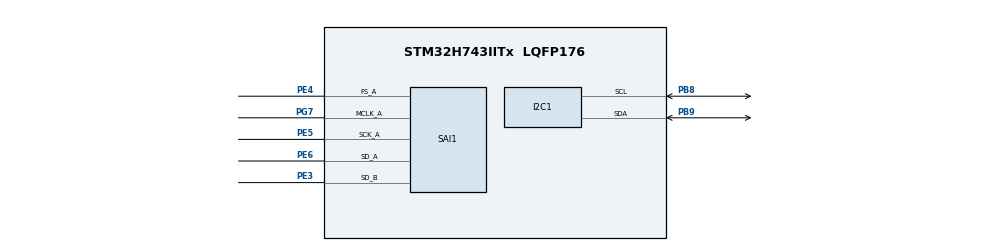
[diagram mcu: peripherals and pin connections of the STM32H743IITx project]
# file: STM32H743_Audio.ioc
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CORTEX_M7.AccessPermission-Cortex_Memory_Protection_Unit_Region1_Settings=MPU_REGION_FULL_ACCESS
CORTEX_M7.BaseAddress-Cortex_Memory_Protection_Unit_Region1_Settings=0x30000000
CORTEX_M7.CPU_DCache=Enabled
CORTEX_M7.CPU_ICache=Enabled
CORTEX_M7.DisableExec-Cortex_Memory_Protection_Unit_Region0_Settings=MPU_INSTRUCTION_ACCESS_DISABLE
CORTEX_M7.DisableExec-Cortex_Memory_Protection_Unit_Region1_Settings=MPU_INSTRUCTION_ACCESS_DISABLE
CORTEX_M7.Enable-Cortex_Memory_Protection_Unit_Region0_Settings=MPU_REGION_ENABLE
CORTEX_M7.Enable-Cortex_Memory_Protection_Unit_Region1_Settings=MPU_REGION_ENABLE
CORTEX_M7.IsBufferable-Cortex_Memory_Protection_Unit_Region1_Settings=MPU_ACCESS_NOT_BUFFERABLE
CORTEX_M7.IsCacheable-Cortex_Memory_Protection_Unit_Region1_Settings=MPU_ACCESS_NOT_CACHEABLE
CORTEX_M7.IsShareable-Cortex_Memory_Protection_Unit_Region0_Settings=MPU_ACCESS_SHAREABLE
CORTEX_M7.IsShareable-Cortex_Memory_Protection_Unit_Region1_Settings=MPU_ACCESS_SHAREABLE
CORTEX_M7.MPU_Control=MPU_PRIVILEGED_DEFAULT
CORTEX_M7.Size-Cortex_Memory_Protection_Unit_Region0_Settings=MPU_REGION_SIZE_4GB
CORTEX_M7.Size-Cortex_Memory_Protection_Unit_Region1_Settings=MPU_REGION_SIZE_32KB
CORTEX_M7.SubRegionDisable-Cortex_Memory_Protection_Unit_Region0_Settings=0x87
Dma.Request0=SAI1_A
Dma.Request1=SAI1_B
Dma.SAI1_A.0.Direction=DMA_MEMORY_TO_PERIPH
Dma.SAI1_A.0.EventEnable=DISABLE
Dma.SAI1_A.0.FIFOMode=DMA_FIFOMODE_DISABLE
Dma.SAI1_A.0.Instance=DMA2_Stream0
Dma.SAI1_A.0.MemDataAlignment=DMA_MDATAALIGN_WORD
Dma.SAI1_A.0.MemInc=DMA_MINC_ENABLE
Dma.SAI1_A.0.Mode=DMA_CIRCULAR
Dma.SAI1_A.0.PeriphDataAlignment=DMA_PDATAALIGN_WORD
Dma.SAI1_A.0.PeriphInc=DMA_PINC_DISABLE
Dma.SAI1_A.0.Polarity=HAL_DMAMUX_REQ_GEN_RISING
Dma.SAI1_A.0.Priority=DMA_PRIORITY_VERY_HIGH
Dma.SAI1_A.0.RequestNumber=1
Dma.SAI1_A.0.SignalID=NONE
Dma.SAI1_A.0.SyncEnable=DISABLE
Dma.SAI1_A.0.SyncPolarity=HAL_DMAMUX_SYNC_NO_EVENT
Dma.SAI1_A.0.SyncRequestNumber=1
Dma.SAI1_A.0.SyncSignalID=NONE
Dma.SAI1_B.1.Direction=DMA_PERIPH_TO_MEMORY
Dma.SAI1_B.1.EventEnable=DISABLE
Dma.SAI1_B.1.FIFOMode=DMA_FIFOMODE_DISABLE
Dma.SAI1_B.1.Instance=DMA2_Stream1
Dma.SAI1_B.1.MemDataAlignment=DMA_MDATAALIGN_WORD
Dma.SAI1_B.1.MemInc=DMA_MINC_ENABLE
Dma.SAI1_B.1.Mode=DMA_CIRCULAR
Dma.SAI1_B.1.PeriphDataAlignment=DMA_PDATAALIGN_WORD
Dma.SAI1_B.1.PeriphInc=DMA_PINC_DISABLE
Dma.SAI1_B.1.Polarity=HAL_DMAMUX_REQ_GEN_RISING
Dma.SAI1_B.1.Priority=DMA_PRIORITY_VERY_HIGH
Dma.SAI1_B.1.RequestNumber=1
Dma.SAI1_B.1.SignalID=NONE
Dma.SAI1_B.1.SyncEnable=DISABLE
Dma.SAI1_B.1.SyncPolarity=HAL_DMAMUX_SYNC_NO_EVENT
Dma.SAI1_B.1.SyncRequestNumber=1
Dma.SAI1_B.1.SyncSignalID=NONE
I2C1.Timing=0x10C0ECFF
Mcu.Family=STM32H7
Mcu.Name=STM32H743IITx
Mcu.Package=LQFP176
NVIC.DMA2_Stream0_IRQn=true\:5\:0\:false\:false\:true\:false\:true\:true
NVIC.DMA2_Stream1_IRQn=true\:5\:0\:false\:false\:true\:false\:true\:true
NVIC.PriorityGroup=NVIC_PRIORITYGROUP_4
PA13\ (JTMS/SWDIO).Mode=Serial_Wire
PA13\ (JTMS/SWDIO).Signal=DEBUG_JTMS-SWDIO
PA14\ (JTCK/SWCLK).Mode=Serial_Wire
PA14\ (JTCK/SWCLK).Signal=DEBUG_JTCK-SWCLK
PB8.GPIO_Speed=GPIO_SPEED_FREQ_VERY_HIGH
PB8.Mode=I2C
PB8.Signal=I2C1_SCL
PB9.GPIO_Speed=GPIO_SPEED_FREQ_VERY_HIGH
PB9.Mode=I2C
PB9.Signal=I2C1_SDA
PE3.GPIO_Speed=GPIO_SPEED_FREQ_VERY_HIGH
PE3.Mode=SAI_B_SyncSlave
PE3.Signal=SAI1_SD_B
PE4.GPIO_Speed=GPIO_SPEED_FREQ_VERY_HIGH
PE4.Mode=SAI_A_MasterWithClock
PE4.Signal=SAI1_FS_A
PE5.GPIO_Speed=GPIO_SPEED_FREQ_VERY_HIGH
PE5.Mode=SAI_A_MasterWithClock
PE5.Signal=SAI1_SCK_A
PE6.GPIO_Speed=GPIO_SPEED_FREQ_VERY_HIGH
PE6.Mode=SAI_A_MasterWithClock
PE6.Signal=SAI1_SD_A
PG7.GPIO_Speed=GPIO_SPEED_FREQ_VERY_HIGH
PG7.Mode=SAI_A_MasterWithClock
PG7.Signal=SAI1_MCLK_A
ProjectManager.HeapSize=0x200
ProjectManager.StackSize=0x400
ProjectManager.TargetToolchain=MDK-ARM V5.32
RCC.ADCFreq_Value=129000000
RCC.APB1Freq_Value=100000000
RCC.APB2Freq_Value=100000000
RCC.APB3Freq_Value=100000000
RCC.APB4Freq_Value=100000000
RCC.CortexFreq_Value=400000000
RCC.D1PPRE=RCC_APB3_DIV2
RCC.D2PPRE1=RCC_APB1_DIV2
RCC.D2PPRE2=RCC_APB2_DIV2
RCC.D3PPRE=RCC_APB4_DIV2
RCC.DIVM1=16
RCC.DIVM3=40
RCC.DIVN1=200
RCC.DIVN3=192
RCC.DIVP3=25
RCC.HCLKFreq_Value=200000000
RCC.HPRE=RCC_HCLK_DIV2
RCC.PLLSourceVirtual=RCC_PLLSOURCE_HSI
RCC.SAI1CLockSelection=RCC_SAI1CLKSOURCE_PLL3
RCC.SYSCLKFreq_VALUE=400000000
RCC.SYSCLKSource=RCC_SYSCLKSOURCE_PLLCLK
RCC.USBFreq_Value=400000000
SAI1.AudioFrequency-SAI_A_MasterWithClock=SAI_AUDIO_FREQUENCY_48K
SAI1.BasicDataSize-SAI_A_MasterWithClock=SAI_PROTOCOL_DATASIZE_24BIT
SAI1.BasicDataSize-SAI_B_SyncSlave=SAI_PROTOCOL_DATASIZE_24BIT
SAI1.BasicProtocol-SAI_A_MasterWithClock=SAI_I2S_STANDARD
SAI1.BasicProtocol-SAI_B_SyncSlave=SAI_I2S_STANDARD
SAI1.ErrorAudioFreq-SAI_A_MasterWithClock=0.0 %
SAI1.InitProtocol-SAI_A_MasterWithClock=Enable
SAI1.InitProtocol-SAI_B_SyncSlave=Enable
SAI1.Instance-SAI_A_MasterWithClock=SAI$Index_Block_A
SAI1.Instance-SAI_B_SyncSlave=SAI$Index_Block_B
SAI1.MClockEnable-SAI_A_MasterWithClock=SAI_MASTERCLOCK_ENABLE
SAI1.RealAudioFreq-SAI_A_MasterWithClock=48.0 KHz
SAI1.VirtualMode-SAI_A_MasterWithClock=VM_MASTER
SAI1.VirtualMode-SAI_B_SyncSlave=VM_SLAVE
SAI1.VirtualProtocol-SAI_A_BASIC=VM_BASIC_PROTOCOL
SAI1.VirtualProtocol-SAI_B_BASIC=VM_BASIC_PROTOCOL
VP_MEMORYMAP_VS_MEMORYMAP.Mode=CurAppReg
VP_SAI1_VP_$IpInstance_SAIA_SAI_BASIC.Mode=SAI_A_BASIC
VP_SAI1_VP_$IpInstance_SAIB_SAI_BASIC.Mode=SAI_B_BASIC
board=custom

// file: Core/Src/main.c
/* USER CODE BEGIN Header */
/**
  ******************************************************************************
  * @file           : main.c
  * @brief          : Main program body
  ******************************************************************************
  * @attention
  *
  * Copyright (c) 2026 STMicroelectronics.
  * All rights reserved.
  *
  * This software is licensed under terms that can be found in the LICENSE file
  * in the root directory of this software component.
  * If no LICENSE file comes with this software, it is provided AS-IS.
  *
  ******************************************************************************
  */
/* USER CODE END Header */
#include "main.h"
#include "dma.h"
#include "i2c.h"
#include "sai.h"
#include "gpio.h"

/* USER CODE BEGIN Includes */
#include "audio_app.h"
#if defined(AUDIO_BOARD_ENABLE_LVGL_UI) && AUDIO_BOARD_ENABLE_LVGL_UI
#include "lvgl_ui.h"
#endif

/* USER CODE END Includes */

void SystemClock_Config(void);
void PeriphCommonClock_Config(void);
static void MPU_Config(void);

int main(void)
{

  /* MPU Configuration--------------------------------------------------------*/
  MPU_Config();

  /* Enable the CPU Cache */

  /* Enable I-Cache---------------------------------------------------------*/
  SCB_EnableICache();

  /* Enable D-Cache---------------------------------------------------------*/
  SCB_EnableDCache();

  /* MCU Configuration--------------------------------------------------------*/

  /* Reset of all peripherals, Initializes the Flash interface and the Systick. */
  HAL_Init();

  /* Configure the system clock */
  SystemClock_Config();

  /* Configure the peripherals common clocks */
  PeriphCommonClock_Config();

  /* Initialize all configured peripherals */
  MX_DMA_Init();
  MX_GPIO_Init();
  MX_I2C1_Init();
  MX_SAI1_Init();
  /* USER CODE BEGIN 2 */
  g_audio_app_status = (int32_t)AudioApp_Init();
#if defined(AUDIO_BOARD_ENABLE_LVGL_UI) && AUDIO_BOARD_ENABLE_LVGL_UI
  /* Display faults have their own g_lvgl_ui_status; do not overwrite audio diagnostics. */
  (void)LvglUi_Init();
#endif

  /* USER CODE END 2 */

  /* Infinite loop */
  while (1)
  {

    /* USER CODE BEGIN 3 */
    (void)AudioApp_Service();
#if defined(AUDIO_BOARD_ENABLE_LVGL_UI) && AUDIO_BOARD_ENABLE_LVGL_UI
    LvglUi_Service();
#endif
    __WFI();
  }
  /* USER CODE END 3 */
}

void SystemClock_Config(void)
{
  RCC_OscInitTypeDef RCC_OscInitStruct = {0};
  RCC_ClkInitTypeDef RCC_ClkInitStruct = {0};

  /** Supply configuration update enable
  */
  HAL_PWREx_ConfigSupply(PWR_LDO_SUPPLY);

  /** Configure the main internal regulator output voltage
  */
  __HAL_PWR_VOLTAGESCALING_CONFIG(PWR_REGULATOR_VOLTAGE_SCALE1);

  while(!__HAL_PWR_GET_FLAG(PWR_FLAG_VOSRDY)) {}

  /** Initializes the RCC Oscillators according to the specified parameters
  * in the RCC_OscInitTypeDef structure.
  */
  RCC_OscInitStruct.OscillatorType = RCC_OSCILLATORTYPE_HSI;
  RCC_OscInitStruct.HSIState = RCC_HSI_DIV1;
  RCC_OscInitStruct.HSICalibrationValue = RCC_HSICALIBRATION_DEFAULT;
  RCC_OscInitStruct.PLL.PLLState = RCC_PLL_ON;
  RCC_OscInitStruct.PLL.PLLSource = RCC_PLLSOURCE_HSI;
  RCC_OscInitStruct.PLL.PLLM = 16;
  RCC_OscInitStruct.PLL.PLLN = 200;
  RCC_OscInitStruct.PLL.PLLP = 2;
  RCC_OscInitStruct.PLL.PLLQ = 2;
  RCC_OscInitStruct.PLL.PLLR = 2;
  RCC_OscInitStruct.PLL.PLLRGE = RCC_PLL1VCIRANGE_2;
  RCC_OscInitStruct.PLL.PLLVCOSEL = RCC_PLL1VCOWIDE;
  RCC_OscInitStruct.PLL.PLLFRACN = 0;
  if (HAL_RCC_OscConfig(&RCC_OscInitStruct) != HAL_OK)
  {
    Error_Handler();
  }

  /** Initializes the CPU, AHB and APB buses clocks
  */
  RCC_ClkInitStruct.ClockType = RCC_CLOCKTYPE_HCLK|RCC_CLOCKTYPE_SYSCLK
                              |RCC_CLOCKTYPE_PCLK1|RCC_CLOCKTYPE_PCLK2
                              |RCC_CLOCKTYPE_D3PCLK1|RCC_CLOCKTYPE_D1PCLK1;
  RCC_ClkInitStruct.SYSCLKSource = RCC_SYSCLKSOURCE_PLLCLK;
  RCC_ClkInitStruct.SYSCLKDivider = RCC_SYSCLK_DIV1;
  RCC_ClkInitStruct.AHBCLKDivider = RCC_HCLK_DIV2;
  RCC_ClkInitStruct.APB3CLKDivider = RCC_APB3_DIV2;
  RCC_ClkInitStruct.APB1CLKDivider = RCC_APB1_DIV2;
  RCC_ClkInitStruct.APB2CLKDivider = RCC_APB2_DIV2;
  RCC_ClkInitStruct.APB4CLKDivider = RCC_APB4_DIV2;

  if (HAL_RCC_ClockConfig(&RCC_ClkInitStruct, FLASH_LATENCY_2) != HAL_OK)
  {
    Error_Handler();
  }
}

void PeriphCommonClock_Config(void)
{
  RCC_PeriphCLKInitTypeDef PeriphClkInitStruct = {0};

  /** Initializes the peripherals clock
  */
  PeriphClkInitStruct.PeriphClockSelection = RCC_PERIPHCLK_SAI1;
  PeriphClkInitStruct.PLL3.PLL3M = 40;
  PeriphClkInitStruct.PLL3.PLL3N = 192;
  PeriphClkInitStruct.PLL3.PLL3P = 25;
  PeriphClkInitStruct.PLL3.PLL3Q = 2;
  PeriphClkInitStruct.PLL3.PLL3R = 2;
  PeriphClkInitStruct.PLL3.PLL3RGE = RCC_PLL3VCIRANGE_0;
  PeriphClkInitStruct.PLL3.PLL3VCOSEL = RCC_PLL3VCOWIDE;
  PeriphClkInitStruct.PLL3.PLL3FRACN = 0;
  PeriphClkInitStruct.Sai1ClockSelection = RCC_SAI1CLKSOURCE_PLL3;
  if (HAL_RCCEx_PeriphCLKConfig(&PeriphClkInitStruct) != HAL_OK)
  {
    Error_Handler();
  }
}

 /* MPU Configuration */

void MPU_Config(void)
{
  MPU_Region_InitTypeDef MPU_InitStruct = {0};

  /* Disables the MPU */
  HAL_MPU_Disable();

  /** Initializes and configures the Region and the memory to be protected
  */
  MPU_InitStruct.Enable = MPU_REGION_ENABLE;
  MPU_InitStruct.Number = MPU_REGION_NUMBER0;
  MPU_InitStruct.BaseAddress = 0x0;
  MPU_InitStruct.Size = MPU_REGION_SIZE_4GB;
  MPU_InitStruct.SubRegionDisable = 0x87;
  MPU_InitStruct.TypeExtField = MPU_TEX_LEVEL0;
  MPU_InitStruct.AccessPermission = MPU_REGION_NO_ACCESS;
  MPU_InitStruct.DisableExec = MPU_INSTRUCTION_ACCESS_DISABLE;
  MPU_InitStruct.IsShareable = MPU_ACCESS_SHAREABLE;
  MPU_InitStruct.IsCacheable = MPU_ACCESS_NOT_CACHEABLE;
  MPU_InitStruct.IsBufferable = MPU_ACCESS_NOT_BUFFERABLE;

  HAL_MPU_ConfigRegion(&MPU_InitStruct);

  /** Initializes and configures the Region and the memory to be protected
  */
  MPU_InitStruct.Number = MPU_REGION_NUMBER1;
  MPU_InitStruct.BaseAddress = 0x30000000;
  MPU_InitStruct.Size = MPU_REGION_SIZE_32KB;
  MPU_InitStruct.SubRegionDisable = 0x0;
  MPU_InitStruct.AccessPermission = MPU_REGION_FULL_ACCESS;

  HAL_MPU_ConfigRegion(&MPU_InitStruct);
  /* Enables the MPU */
  HAL_MPU_Enable(MPU_PRIVILEGED_DEFAULT);

}

void Error_Handler(void)
{
  __disable_irq();
  while (1)
  {
  }
}
